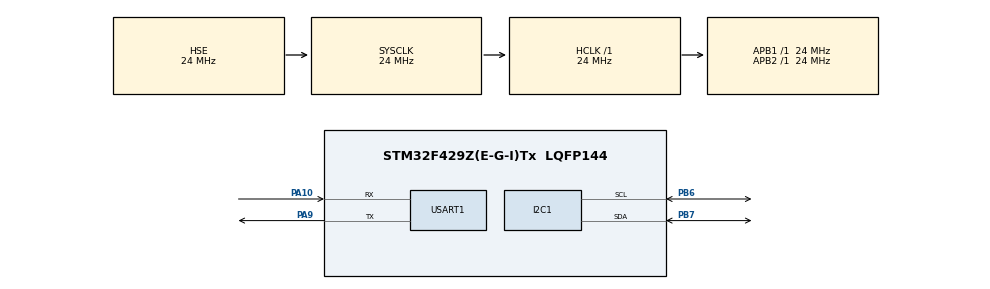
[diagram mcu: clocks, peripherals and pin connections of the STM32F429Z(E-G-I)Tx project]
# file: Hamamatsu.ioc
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I2C1.I2C_Mode=I2C_Fast
Mcu.Family=STM32F4
Mcu.Name=STM32F429Z(E-G-I)Tx
Mcu.Package=LQFP144
NVIC.PriorityGroup=NVIC_PRIORITYGROUP_4
NVIC.TIM5_IRQn=true\:0\:0\:false\:false\:true\:true
PA10.Mode=Asynchronous
PA10.Signal=USART1_RX
PA9.Mode=Asynchronous
PA9.Signal=USART1_TX
PB6.Mode=I2C
PB6.Signal=I2C1_SCL
PB7.Mode=I2C
PB7.Signal=I2C1_SDA
PH0/OSC_IN.Mode=HSE-External-Oscillator
PH0/OSC_IN.Signal=RCC_OSC_IN
PH1/OSC_OUT.Mode=HSE-External-Oscillator
PH1/OSC_OUT.Signal=RCC_OSC_OUT
ProjectManager.HeapSize=0x200
ProjectManager.StackSize=0x400
ProjectManager.TargetToolchain=EWARM
RCC.48MHZClocksFreq_Value=72000000
RCC.AHBFreq_Value=24000000
RCC.APB1Freq_Value=24000000
RCC.APB1TimFreq_Value=24000000
RCC.APB2Freq_Value=24000000
RCC.APB2TimFreq_Value=24000000
RCC.CortexFreq_Value=24000000
RCC.HCLKFreq_Value=24000000
RCC.HSE_VALUE=24000000
RCC.HSI_VALUE=16000000
RCC.LSE_VALUE=32768
RCC.PLLSourceVirtual=RCC_PLLSOURCE_HSE
RCC.SYSCLKFreq_VALUE=24000000
RCC.SYSCLKSource=RCC_SYSCLKSOURCE_HSE
RCC.VCOOutputFreq_Value=288000000
TIM5.Period=50
TIM5.Prescaler=23999
TIM5.TIM_MasterOutputTrigger=TIM_TRGO_UPDATE
USART1.VirtualMode=VM_ASYNC
VP_TIM5_VS_ClockSourceINT.Mode=Internal
board=Hamamatsu

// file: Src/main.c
/**
  ******************************************************************************
  * File Name          : main.c
  * Description        : Main program body
  ******************************************************************************
  ** This notice applies to any and all portions of this file
  * that are not between comment pairs USER CODE BEGIN and
  * USER CODE END. Other portions of this file, whether
  * inserted by the user or by software development tools
  * are owned by their respective copyright owners.
  *
  * COPYRIGHT(c) 2018 STMicroelectronics
  *
  * Redistribution and use in source and binary forms, with or without modification,
  * are permitted provided that the following conditions are met:
  *   1. Redistributions of source code must retain the above copyright notice,
  *      this list of conditions and the following disclaimer.
  *   2. Redistributions in binary form must reproduce the above copyright notice,
  *      this list of conditions and the following disclaimer in the documentation
  *      and/or other materials provided with the distribution.
  *   3. Neither the name of STMicroelectronics nor the names of its contributors
  *      may be used to endorse or promote products derived from this software
  *      without specific prior written permission.
  *
  * THIS SOFTWARE IS PROVIDED BY THE COPYRIGHT HOLDERS AND CONTRIBUTORS "AS IS"
  * AND ANY EXPRESS OR IMPLIED WARRANTIES, INCLUDING, BUT NOT LIMITED TO, THE
  * IMPLIED WARRANTIES OF MERCHANTABILITY AND FITNESS FOR A PARTICULAR PURPOSE ARE
  * DISCLAIMED. IN NO EVENT SHALL THE COPYRIGHT HOLDER OR CONTRIBUTORS BE LIABLE
  * FOR ANY DIRECT, INDIRECT, INCIDENTAL, SPECIAL, EXEMPLARY, OR CONSEQUENTIAL
  * DAMAGES (INCLUDING, BUT NOT LIMITED TO, PROCUREMENT OF SUBSTITUTE GOODS OR
  * SERVICES; LOSS OF USE, DATA, OR PROFITS; OR BUSINESS INTERRUPTION) HOWEVER
  * CAUSED AND ON ANY THEORY OF LIABILITY, WHETHER IN CONTRACT, STRICT LIABILITY,
  * OR TORT (INCLUDING NEGLIGENCE OR OTHERWISE) ARISING IN ANY WAY OUT OF THE USE
  * OF THIS SOFTWARE, EVEN IF ADVISED OF THE POSSIBILITY OF SUCH DAMAGE.
  *
  ******************************************************************************
  */
#include "main.h"
#include "stm32f4xx_hal.h"

/* USER CODE BEGIN Includes */
#include "Hamamatsu.h"
/* USER CODE END Includes */

I2C_HandleTypeDef hi2c1;

TIM_HandleTypeDef htim5;

UART_HandleTypeDef huart1;

/* USER CODE BEGIN PV */
/* Private variables ---------------------------------------------------------*/

/* USER CODE END PV */

void SystemClock_Config(void);
static void MX_GPIO_Init(void);
static void MX_I2C1_Init(void);
static void MX_USART1_UART_Init(void);
static void MX_TIM5_Init(void);

/* USER CODE BEGIN PFP */
/* Private function prototypes -----------------------------------------------*/

/* USER CODE END PFP */

int main(void)
{

  /* MCU Configuration----------------------------------------------------------*/

  /* Reset of all peripherals, Initializes the Flash interface and the Systick. */
  HAL_Init();

  /* Configure the system clock */
  SystemClock_Config();

  /* Initialize all configured peripherals */
  MX_GPIO_Init();
  MX_I2C1_Init();
  MX_USART1_UART_Init();
  MX_TIM5_Init();

  /* USER CODE BEGIN 2 */
  //Hamamatsu_INIT(&hi2c1, &huart1);
  Fixed_teme_mode(&hi2c1, &huart1, &htim5);

  //Manual_setting_mode(&hi2c1, &huart1);

  /* USER CODE END 2 */

  /* Infinite loop */
  while (1)
  {

  }

}

/** System Clock Configuration
*/
void SystemClock_Config(void)
{

  RCC_OscInitTypeDef RCC_OscInitStruct;
  RCC_ClkInitTypeDef RCC_ClkInitStruct;

    /**Configure the main internal regulator output voltage
    */
  __HAL_RCC_PWR_CLK_ENABLE();

  __HAL_PWR_VOLTAGESCALING_CONFIG(PWR_REGULATOR_VOLTAGE_SCALE3);

    /**Initializes the CPU, AHB and APB busses clocks
    */
  RCC_OscInitStruct.OscillatorType = RCC_OSCILLATORTYPE_HSE;
  RCC_OscInitStruct.HSEState = RCC_HSE_ON;
  RCC_OscInitStruct.PLL.PLLState = RCC_PLL_NONE;
  if (HAL_RCC_OscConfig(&RCC_OscInitStruct) != HAL_OK)
  {
    _Error_Handler(__FILE__, __LINE__);
  }

    /**Initializes the CPU, AHB and APB busses clocks
    */
  RCC_ClkInitStruct.ClockType = RCC_CLOCKTYPE_HCLK|RCC_CLOCKTYPE_SYSCLK
                              |RCC_CLOCKTYPE_PCLK1|RCC_CLOCKTYPE_PCLK2;
  RCC_ClkInitStruct.SYSCLKSource = RCC_SYSCLKSOURCE_HSE;
  RCC_ClkInitStruct.AHBCLKDivider = RCC_SYSCLK_DIV1;
  RCC_ClkInitStruct.APB1CLKDivider = RCC_HCLK_DIV1;
  RCC_ClkInitStruct.APB2CLKDivider = RCC_HCLK_DIV1;

  if (HAL_RCC_ClockConfig(&RCC_ClkInitStruct, FLASH_LATENCY_0) != HAL_OK)
  {
    _Error_Handler(__FILE__, __LINE__);
  }

    /**Configure the Systick interrupt time
    */
  HAL_SYSTICK_Config(HAL_RCC_GetHCLKFreq()/1000);

    /**Configure the Systick
    */
  HAL_SYSTICK_CLKSourceConfig(SYSTICK_CLKSOURCE_HCLK);

  /* SysTick_IRQn interrupt configuration */
  HAL_NVIC_SetPriority(SysTick_IRQn, 0, 0);
}

/* I2C1 init function */
static void MX_I2C1_Init(void)
{

  hi2c1.Instance = I2C1;
  hi2c1.Init.ClockSpeed = 400000;
  hi2c1.Init.DutyCycle = I2C_DUTYCYCLE_2;
  hi2c1.Init.OwnAddress1 = 0;
  hi2c1.Init.AddressingMode = I2C_ADDRESSINGMODE_7BIT;
  hi2c1.Init.DualAddressMode = I2C_DUALADDRESS_DISABLE;
  hi2c1.Init.OwnAddress2 = 0;
  hi2c1.Init.GeneralCallMode = I2C_GENERALCALL_DISABLE;
  hi2c1.Init.NoStretchMode = I2C_NOSTRETCH_DISABLE;
  if (HAL_I2C_Init(&hi2c1) != HAL_OK)
  {
    _Error_Handler(__FILE__, __LINE__);
  }

}

/* TIM5 init function */
static void MX_TIM5_Init(void)
{

  TIM_ClockConfigTypeDef sClockSourceConfig;
  TIM_MasterConfigTypeDef sMasterConfig;

  htim5.Instance = TIM5;
  htim5.Init.Prescaler = 23999;
  htim5.Init.CounterMode = TIM_COUNTERMODE_UP;
  htim5.Init.Period = 1;
  htim5.Init.ClockDivision = TIM_CLOCKDIVISION_DIV1;
  if (HAL_TIM_Base_Init(&htim5) != HAL_OK)
  {
    _Error_Handler(__FILE__, __LINE__);
  }

  sClockSourceConfig.ClockSource = TIM_CLOCKSOURCE_INTERNAL;
  if (HAL_TIM_ConfigClockSource(&htim5, &sClockSourceConfig) != HAL_OK)
  {
    _Error_Handler(__FILE__, __LINE__);
  }

  sMasterConfig.MasterOutputTrigger = TIM_TRGO_UPDATE;
  sMasterConfig.MasterSlaveMode = TIM_MASTERSLAVEMODE_DISABLE;
  if (HAL_TIMEx_MasterConfigSynchronization(&htim5, &sMasterConfig) != HAL_OK)
  {
    _Error_Handler(__FILE__, __LINE__);
  }

}

/* USART1 init function */
static void MX_USART1_UART_Init(void)
{

  huart1.Instance = USART1;
  huart1.Init.BaudRate = 115200;
  huart1.Init.WordLength = UART_WORDLENGTH_8B;
  huart1.Init.StopBits = UART_STOPBITS_1;
  huart1.Init.Parity = UART_PARITY_NONE;
  huart1.Init.Mode = UART_MODE_TX_RX;
  huart1.Init.HwFlowCtl = UART_HWCONTROL_NONE;
  huart1.Init.OverSampling = UART_OVERSAMPLING_16;
  if (HAL_UART_Init(&huart1) != HAL_OK)
  {
    _Error_Handler(__FILE__, __LINE__);
  }

}

/** Configure pins as
        * Analog
        * Input
        * Output
        * EVENT_OUT
        * EXTI
*/
static void MX_GPIO_Init(void)
{

  /* GPIO Ports Clock Enable */
  __HAL_RCC_GPIOH_CLK_ENABLE();
  __HAL_RCC_GPIOA_CLK_ENABLE();
  __HAL_RCC_GPIOB_CLK_ENABLE();

}

/* USER CODE BEGIN 4 */

void TIM5_IRQHandler(void)
{
    if(TIM5->SR & TIM_SR_UIF) // if UIF flag is set
    {
      TIM5->SR &= ~TIM_SR_UIF; // clear UIF flag

      //I2C_WriteREG(&hi2c1, RGB_sensor_control, 0x61);

      I2C_ReadData(&hi2c1,&huart1);

      //I2C_WriteREG(&hi2c1, RGB_sensor_control, 0x01);
    }
}

/* USER CODE END 4 */

void _Error_Handler(char * file, int line)
{
  while(1)
  {
  }
}

/************************ (C) COPYRIGHT STMicroelectronics *****END OF FILE****/
